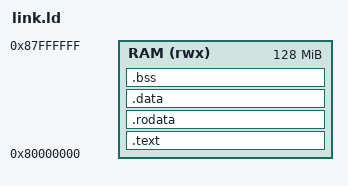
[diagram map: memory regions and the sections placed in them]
/* RISC-V 64 default linker script for QEMU virt machine.
 *
 * In practice, the linker script is generated from the board RON memory map.
 * This is a fallback / reference.
 */

OUTPUT_ARCH(riscv)
ENTRY(_start)

MEMORY
{
    RAM (rwx) : ORIGIN = 0x80000000, LENGTH = 128M
}

SECTIONS
{
    .text : {
        *(.text.entry)
        *(.text .text.*)
    } > RAM

    .rodata : ALIGN(8) {
        *(.rodata .rodata.*)
    } > RAM

    .data : ALIGN(8) {
        *(.data .data.*)
    } > RAM

    .bss (NOLOAD) : ALIGN(8) {
        _bss_start = .;
        *(.bss .bss.*)
        *(COMMON)
        _bss_end = .;
    } > RAM

    . = ALIGN(16);
    . = . + 0x10000;
    _stack_top = .;
}
